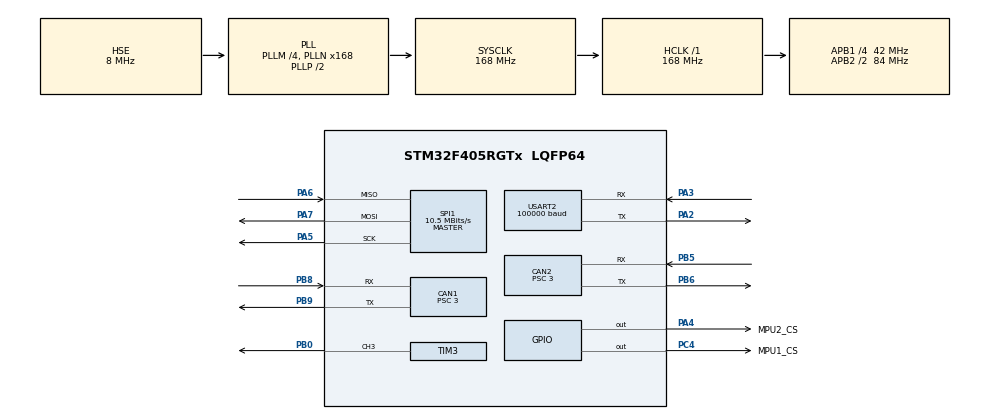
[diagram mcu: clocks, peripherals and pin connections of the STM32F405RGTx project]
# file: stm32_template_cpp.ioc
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CAN1.ABOM=ENABLE
CAN1.BS1=CAN_BS1_9TQ
CAN1.BS2=CAN_BS2_4TQ
CAN1.CalculateBaudRate=1000000
CAN1.CalculateTimeBit=1000
CAN1.CalculateTimeQuantum=71.42857142857143
CAN1.NART=ENABLE
CAN1.Prescaler=3
CAN2.ABOM=ENABLE
CAN2.BS1=CAN_BS1_9TQ
CAN2.BS2=CAN_BS2_4TQ
CAN2.CalculateBaudRate=1000000
CAN2.CalculateTimeBit=1000
CAN2.CalculateTimeQuantum=71.42857142857143
CAN2.NART=ENABLE
CAN2.Prescaler=3
Dma.Request0=USART2_RX
Dma.USART2_RX.0.Direction=DMA_PERIPH_TO_MEMORY
Dma.USART2_RX.0.FIFOMode=DMA_FIFOMODE_DISABLE
Dma.USART2_RX.0.Instance=DMA1_Stream5
Dma.USART2_RX.0.MemDataAlignment=DMA_MDATAALIGN_BYTE
Dma.USART2_RX.0.MemInc=DMA_MINC_ENABLE
Dma.USART2_RX.0.Mode=DMA_CIRCULAR
Dma.USART2_RX.0.PeriphDataAlignment=DMA_PDATAALIGN_BYTE
Dma.USART2_RX.0.PeriphInc=DMA_PINC_DISABLE
Dma.USART2_RX.0.Priority=DMA_PRIORITY_HIGH
FREERTOS.INCLUDE_vTaskDelayUntil=1
FREERTOS.Tasks01=defaultTask,0,128,StartDefaultTask,Default,NULL,Dynamic,NULL,NULL
FREERTOS.configMINIMAL_STACK_SIZE=64
Mcu.Family=STM32F4
Mcu.Name=STM32F405RGTx
Mcu.Package=LQFP64
NVIC.CAN1_RX0_IRQn=true\:5\:0\:false\:false\:true\:true\:true\:true\:true
NVIC.CAN1_RX1_IRQn=true\:5\:0\:false\:false\:true\:true\:true\:true\:true
NVIC.CAN2_RX0_IRQn=true\:5\:0\:false\:false\:true\:true\:true\:true\:true
NVIC.CAN2_RX1_IRQn=true\:5\:0\:false\:false\:true\:true\:true\:true\:true
NVIC.DMA1_Stream5_IRQn=true\:5\:0\:false\:false\:true\:true\:false\:true\:true
NVIC.PriorityGroup=NVIC_PRIORITYGROUP_4
NVIC.TIM6_DAC_IRQn=true\:15\:0\:false\:false\:true\:false\:false\:true\:true
NVIC.TIM7_IRQn=true\:5\:0\:false\:false\:true\:true\:true\:true\:true
NVIC.TimeBase=TIM6_DAC_IRQn
NVIC.TimeBaseIP=TIM6
NVIC.USART2_IRQn=true\:5\:0\:false\:false\:true\:true\:true\:true\:true
PA13.Mode=Serial_Wire
PA13.Signal=SYS_JTMS-SWDIO
PA14.Mode=Serial_Wire
PA14.Signal=SYS_JTCK-SWCLK
PA2.Mode=Asynchronous
PA2.Signal=USART2_TX
PA3.Mode=Asynchronous
PA3.Signal=USART2_RX
PA4.GPIO_Label=MPU2_CS
PA4.GPIO_Speed=GPIO_SPEED_FREQ_HIGH
PA4.PinState=GPIO_PIN_SET
PA4.Signal=GPIO_Output
PA5.Mode=Full_Duplex_Master
PA5.Signal=SPI1_SCK
PA6.Mode=Full_Duplex_Master
PA6.Signal=SPI1_MISO
PA7.Mode=Full_Duplex_Master
PA7.Signal=SPI1_MOSI
PB0.Signal=S_TIM3_CH3
PB5.Mode=CAN_Activate
PB5.Signal=CAN2_RX
PB6.Mode=CAN_Activate
PB6.Signal=CAN2_TX
PB8.Mode=CAN_Activate
PB8.Signal=CAN1_RX
PB9.Mode=CAN_Activate
PB9.Signal=CAN1_TX
PC4.GPIO_Label=MPU1_CS
PC4.GPIO_Speed=GPIO_SPEED_FREQ_HIGH
PC4.PinState=GPIO_PIN_SET
PC4.Signal=GPIO_Output
PH0-OSC_IN.Mode=HSE-External-Oscillator
PH0-OSC_IN.Signal=RCC_OSC_IN
PH1-OSC_OUT.Mode=HSE-External-Oscillator
PH1-OSC_OUT.Signal=RCC_OSC_OUT
ProjectManager.HeapSize=0x200
ProjectManager.StackSize=0x400
ProjectManager.TargetToolchain=MDK-ARM V5.32
RCC.48MHZClocksFreq_Value=84000000
RCC.AHBFreq_Value=168000000
RCC.APB1CLKDivider=RCC_HCLK_DIV4
RCC.APB1Freq_Value=42000000
RCC.APB1TimFreq_Value=84000000
RCC.APB2CLKDivider=RCC_HCLK_DIV2
RCC.APB2Freq_Value=84000000
RCC.APB2TimFreq_Value=168000000
RCC.CortexFreq_Value=168000000
RCC.HCLKFreq_Value=168000000
RCC.HSE_VALUE=8000000
RCC.HSI_VALUE=16000000
RCC.LSE_VALUE=32768
RCC.PLLM=4
RCC.PLLN=168
RCC.PLLSourceVirtual=RCC_PLLSOURCE_HSE
RCC.SYSCLKFreq_VALUE=168000000
RCC.SYSCLKSource=RCC_SYSCLKSOURCE_PLLCLK
RCC.VCOOutputFreq_Value=336000000
SH.S_TIM3_CH3.0=TIM3_CH3,PWM Generation3 CH3
SPI1.BaudRatePrescaler=SPI_BAUDRATEPRESCALER_8
SPI1.CalculateBaudRate=10.5 MBits/s
SPI1.Direction=SPI_DIRECTION_2LINES
SPI1.Mode=SPI_MODE_MASTER
SPI1.VirtualType=VM_MASTER
TIM3.Channel-PWM\ Generation3\ CH3=TIM_CHANNEL_3
TIM3.Period=999
TIM3.Prescaler=83
TIM7.Prescaler=83
USART2.BaudRate=100000
USART2.Mode=MODE_RX
USART2.Parity=PARITY_EVEN
USART2.VirtualMode=VM_ASYNC
VP_FREERTOS_VS_CMSIS_V1.Mode=CMSIS_V1
VP_SYS_VS_tim6.Mode=TIM6
VP_TIM3_VS_ClockSourceINT.Mode=Internal
VP_TIM7_VS_ClockSourceINT.Mode=Enable_Timer
board=custom

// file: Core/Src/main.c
/* USER CODE BEGIN Header */
/**
  ******************************************************************************
  * @file           : main.c
  * @brief          : Main program body
  ******************************************************************************
  * @attention
  *
  * Copyright (c) 2023 STMicroelectronics.
  * All rights reserved.
  *
  * This software is licensed under terms that can be found in the LICENSE file
  * in the root directory of this software component.
  * If no LICENSE file comes with this software, it is provided AS-IS.
  *
  ******************************************************************************
  */
/* USER CODE END Header */
#include "main.h"
#include "cmsis_os.h"

/* USER CODE BEGIN Includes */
#include "system_start.h"
/* USER CODE END Includes */

CAN_HandleTypeDef hcan1;
CAN_HandleTypeDef hcan2;

osThreadId defaultTaskHandle;

void SystemClock_Config(void);
static void MX_GPIO_Init(void);
static void MX_DMA_Init(void);
static void MX_CAN1_Init(void);
static void MX_CAN2_Init(void);
static void MX_USART2_UART_Init(void);
static void MX_TIM7_Init(void);
static void MX_SPI1_Init(void);
static void MX_TIM3_Init(void);
void StartDefaultTask(void const * argument);

int main(void)
{
  /* USER CODE BEGIN 1 */
	//__disable_irq();
  /* USER CODE END 1 */

  /* MCU Configuration--------------------------------------------------------*/

  /* Reset of all peripherals, Initializes the Flash interface and the Systick. */
  HAL_Init();

  /* Configure the system clock */
  SystemClock_Config();

  /* Initialize all configured peripherals */
  MX_GPIO_Init();
  MX_DMA_Init();
  MX_CAN1_Init();
  MX_CAN2_Init();
  MX_USART2_UART_Init();
  MX_TIM7_Init();
  MX_SPI1_Init();
  MX_TIM3_Init();
  /* USER CODE BEGIN 2 */
	System_Init();
	//__enable_irq();
  /* USER CODE END 2 */

  /* Create the thread(s) */
  /* definition and creation of defaultTask */
  osThreadDef(defaultTask, StartDefaultTask, osPriorityNormal, 0, 128);
  defaultTaskHandle = osThreadCreate(osThread(defaultTask), NULL);

  /* Start scheduler */
  osKernelStart();

  /* We should never get here as control is now taken by the scheduler */
  /* Infinite loop */
  while (1)
  {

  }
}

void SystemClock_Config(void)
{
  RCC_OscInitTypeDef RCC_OscInitStruct = {0};
  RCC_ClkInitTypeDef RCC_ClkInitStruct = {0};

  /** Configure the main internal regulator output voltage
  */
  __HAL_RCC_PWR_CLK_ENABLE();
  __HAL_PWR_VOLTAGESCALING_CONFIG(PWR_REGULATOR_VOLTAGE_SCALE1);

  /** Initializes the RCC Oscillators according to the specified parameters
  * in the RCC_OscInitTypeDef structure.
  */
  RCC_OscInitStruct.OscillatorType = RCC_OSCILLATORTYPE_HSE;
  RCC_OscInitStruct.HSEState = RCC_HSE_ON;
  RCC_OscInitStruct.PLL.PLLState = RCC_PLL_ON;
  RCC_OscInitStruct.PLL.PLLSource = RCC_PLLSOURCE_HSE;
  RCC_OscInitStruct.PLL.PLLM = 4;
  RCC_OscInitStruct.PLL.PLLN = 168;
  RCC_OscInitStruct.PLL.PLLP = RCC_PLLP_DIV2;
  RCC_OscInitStruct.PLL.PLLQ = 4;
  if (HAL_RCC_OscConfig(&RCC_OscInitStruct) != HAL_OK)
  {
    Error_Handler();
  }

  /** Initializes the CPU, AHB and APB buses clocks
  */
  RCC_ClkInitStruct.ClockType = RCC_CLOCKTYPE_HCLK|RCC_CLOCKTYPE_SYSCLK
                              |RCC_CLOCKTYPE_PCLK1|RCC_CLOCKTYPE_PCLK2;
  RCC_ClkInitStruct.SYSCLKSource = RCC_SYSCLKSOURCE_PLLCLK;
  RCC_ClkInitStruct.AHBCLKDivider = RCC_SYSCLK_DIV1;
  RCC_ClkInitStruct.APB1CLKDivider = RCC_HCLK_DIV4;
  RCC_ClkInitStruct.APB2CLKDivider = RCC_HCLK_DIV2;

  if (HAL_RCC_ClockConfig(&RCC_ClkInitStruct, FLASH_LATENCY_5) != HAL_OK)
  {
    Error_Handler();
  }
}

static void MX_CAN1_Init(void)
{

  hcan1.Instance = CAN1;
  hcan1.Init.Prescaler = 3;
  hcan1.Init.Mode = CAN_MODE_NORMAL;
  hcan1.Init.SyncJumpWidth = CAN_SJW_1TQ;
  hcan1.Init.TimeSeg1 = CAN_BS1_9TQ;
  hcan1.Init.TimeSeg2 = CAN_BS2_4TQ;
  hcan1.Init.TimeTriggeredMode = DISABLE;
  hcan1.Init.AutoBusOff = ENABLE;
  hcan1.Init.AutoWakeUp = DISABLE;
  hcan1.Init.AutoRetransmission = ENABLE;
  hcan1.Init.ReceiveFifoLocked = DISABLE;
  hcan1.Init.TransmitFifoPriority = DISABLE;
  if (HAL_CAN_Init(&hcan1) != HAL_OK)
  {
    Error_Handler();
  }

}

static void MX_CAN2_Init(void)
{

  hcan2.Instance = CAN2;
  hcan2.Init.Prescaler = 3;
  hcan2.Init.Mode = CAN_MODE_NORMAL;
  hcan2.Init.SyncJumpWidth = CAN_SJW_1TQ;
  hcan2.Init.TimeSeg1 = CAN_BS1_9TQ;
  hcan2.Init.TimeSeg2 = CAN_BS2_4TQ;
  hcan2.Init.TimeTriggeredMode = DISABLE;
  hcan2.Init.AutoBusOff = ENABLE;
  hcan2.Init.AutoWakeUp = DISABLE;
  hcan2.Init.AutoRetransmission = ENABLE;
  hcan2.Init.ReceiveFifoLocked = DISABLE;
  hcan2.Init.TransmitFifoPriority = DISABLE;
  if (HAL_CAN_Init(&hcan2) != HAL_OK)
  {
    Error_Handler();
  }

}

static void MX_SPI1_Init(void)
{

  LL_SPI_InitTypeDef SPI_InitStruct = {0};

  LL_GPIO_InitTypeDef GPIO_InitStruct = {0};

  /* Peripheral clock enable */
  LL_APB2_GRP1_EnableClock(LL_APB2_GRP1_PERIPH_SPI1);

  LL_AHB1_GRP1_EnableClock(LL_AHB1_GRP1_PERIPH_GPIOA);
  /**SPI1 GPIO Configuration
  PA5   ------> SPI1_SCK
  PA6   ------> SPI1_MISO
  PA7   ------> SPI1_MOSI
  */
  GPIO_InitStruct.Pin = LL_GPIO_PIN_5|LL_GPIO_PIN_6|LL_GPIO_PIN_7;
  GPIO_InitStruct.Mode = LL_GPIO_MODE_ALTERNATE;
  GPIO_InitStruct.Speed = LL_GPIO_SPEED_FREQ_VERY_HIGH;
  GPIO_InitStruct.OutputType = LL_GPIO_OUTPUT_PUSHPULL;
  GPIO_InitStruct.Pull = LL_GPIO_PULL_NO;
  GPIO_InitStruct.Alternate = LL_GPIO_AF_5;
  LL_GPIO_Init(GPIOA, &GPIO_InitStruct);

  /* SPI1 parameter configuration*/
  SPI_InitStruct.TransferDirection = LL_SPI_FULL_DUPLEX;
  SPI_InitStruct.Mode = LL_SPI_MODE_MASTER;
  SPI_InitStruct.DataWidth = LL_SPI_DATAWIDTH_8BIT;
  SPI_InitStruct.ClockPolarity = LL_SPI_POLARITY_LOW;
  SPI_InitStruct.ClockPhase = LL_SPI_PHASE_1EDGE;
  SPI_InitStruct.NSS = LL_SPI_NSS_SOFT;
  SPI_InitStruct.BaudRate = LL_SPI_BAUDRATEPRESCALER_DIV8;
  SPI_InitStruct.BitOrder = LL_SPI_MSB_FIRST;
  SPI_InitStruct.CRCCalculation = LL_SPI_CRCCALCULATION_DISABLE;
  SPI_InitStruct.CRCPoly = 10;
  LL_SPI_Init(SPI1, &SPI_InitStruct);
  LL_SPI_SetStandard(SPI1, LL_SPI_PROTOCOL_MOTOROLA);

}

static void MX_TIM3_Init(void)
{

  LL_TIM_InitTypeDef TIM_InitStruct = {0};
  LL_TIM_OC_InitTypeDef TIM_OC_InitStruct = {0};

  LL_GPIO_InitTypeDef GPIO_InitStruct = {0};

  /* Peripheral clock enable */
  LL_APB1_GRP1_EnableClock(LL_APB1_GRP1_PERIPH_TIM3);

  TIM_InitStruct.Prescaler = 83;
  TIM_InitStruct.CounterMode = LL_TIM_COUNTERMODE_UP;
  TIM_InitStruct.Autoreload = 999;
  TIM_InitStruct.ClockDivision = LL_TIM_CLOCKDIVISION_DIV1;
  LL_TIM_Init(TIM3, &TIM_InitStruct);
  LL_TIM_DisableARRPreload(TIM3);
  LL_TIM_SetClockSource(TIM3, LL_TIM_CLOCKSOURCE_INTERNAL);
  LL_TIM_OC_EnablePreload(TIM3, LL_TIM_CHANNEL_CH3);
  TIM_OC_InitStruct.OCMode = LL_TIM_OCMODE_PWM1;
  TIM_OC_InitStruct.OCState = LL_TIM_OCSTATE_DISABLE;
  TIM_OC_InitStruct.OCNState = LL_TIM_OCSTATE_DISABLE;
  TIM_OC_InitStruct.CompareValue = 0;
  TIM_OC_InitStruct.OCPolarity = LL_TIM_OCPOLARITY_HIGH;
  LL_TIM_OC_Init(TIM3, LL_TIM_CHANNEL_CH3, &TIM_OC_InitStruct);
  LL_TIM_OC_DisableFast(TIM3, LL_TIM_CHANNEL_CH3);
  LL_TIM_SetTriggerOutput(TIM3, LL_TIM_TRGO_RESET);
  LL_TIM_DisableMasterSlaveMode(TIM3);
  LL_AHB1_GRP1_EnableClock(LL_AHB1_GRP1_PERIPH_GPIOB);
  /**TIM3 GPIO Configuration
  PB0   ------> TIM3_CH3
  */
  GPIO_InitStruct.Pin = LL_GPIO_PIN_0;
  GPIO_InitStruct.Mode = LL_GPIO_MODE_ALTERNATE;
  GPIO_InitStruct.Speed = LL_GPIO_SPEED_FREQ_LOW;
  GPIO_InitStruct.OutputType = LL_GPIO_OUTPUT_PUSHPULL;
  GPIO_InitStruct.Pull = LL_GPIO_PULL_NO;
  GPIO_InitStruct.Alternate = LL_GPIO_AF_2;
  LL_GPIO_Init(GPIOB, &GPIO_InitStruct);

}

static void MX_TIM7_Init(void)
{

  LL_TIM_InitTypeDef TIM_InitStruct = {0};

  /* Peripheral clock enable */
  LL_APB1_GRP1_EnableClock(LL_APB1_GRP1_PERIPH_TIM7);

  /* TIM7 interrupt Init */
  NVIC_SetPriority(TIM7_IRQn, NVIC_EncodePriority(NVIC_GetPriorityGrouping(),5, 0));
  NVIC_EnableIRQ(TIM7_IRQn);

  TIM_InitStruct.Prescaler = 83;
  TIM_InitStruct.CounterMode = LL_TIM_COUNTERMODE_UP;
  TIM_InitStruct.Autoreload = 65535;
  LL_TIM_Init(TIM7, &TIM_InitStruct);
  LL_TIM_DisableARRPreload(TIM7);
  LL_TIM_SetTriggerOutput(TIM7, LL_TIM_TRGO_RESET);
  LL_TIM_DisableMasterSlaveMode(TIM7);

}

static void MX_USART2_UART_Init(void)
{

  LL_USART_InitTypeDef USART_InitStruct = {0};

  LL_GPIO_InitTypeDef GPIO_InitStruct = {0};

  /* Peripheral clock enable */
  LL_APB1_GRP1_EnableClock(LL_APB1_GRP1_PERIPH_USART2);

  LL_AHB1_GRP1_EnableClock(LL_AHB1_GRP1_PERIPH_GPIOA);
  /**USART2 GPIO Configuration
  PA2   ------> USART2_TX
  PA3   ------> USART2_RX
  */
  GPIO_InitStruct.Pin = LL_GPIO_PIN_2|LL_GPIO_PIN_3;
  GPIO_InitStruct.Mode = LL_GPIO_MODE_ALTERNATE;
  GPIO_InitStruct.Speed = LL_GPIO_SPEED_FREQ_VERY_HIGH;
  GPIO_InitStruct.OutputType = LL_GPIO_OUTPUT_PUSHPULL;
  GPIO_InitStruct.Pull = LL_GPIO_PULL_NO;
  GPIO_InitStruct.Alternate = LL_GPIO_AF_7;
  LL_GPIO_Init(GPIOA, &GPIO_InitStruct);

  /* USART2 DMA Init */

  /* USART2_RX Init */
  LL_DMA_SetChannelSelection(DMA1, LL_DMA_STREAM_5, LL_DMA_CHANNEL_4);

  LL_DMA_SetDataTransferDirection(DMA1, LL_DMA_STREAM_5, LL_DMA_DIRECTION_PERIPH_TO_MEMORY);

  LL_DMA_SetStreamPriorityLevel(DMA1, LL_DMA_STREAM_5, LL_DMA_PRIORITY_HIGH);

  LL_DMA_SetMode(DMA1, LL_DMA_STREAM_5, LL_DMA_MODE_CIRCULAR);

  LL_DMA_SetPeriphIncMode(DMA1, LL_DMA_STREAM_5, LL_DMA_PERIPH_NOINCREMENT);

  LL_DMA_SetMemoryIncMode(DMA1, LL_DMA_STREAM_5, LL_DMA_MEMORY_INCREMENT);

  LL_DMA_SetPeriphSize(DMA1, LL_DMA_STREAM_5, LL_DMA_PDATAALIGN_BYTE);

  LL_DMA_SetMemorySize(DMA1, LL_DMA_STREAM_5, LL_DMA_MDATAALIGN_BYTE);

  LL_DMA_DisableFifoMode(DMA1, LL_DMA_STREAM_5);

  /* USART2 interrupt Init */
  NVIC_SetPriority(USART2_IRQn, NVIC_EncodePriority(NVIC_GetPriorityGrouping(),5, 0));
  NVIC_EnableIRQ(USART2_IRQn);

  USART_InitStruct.BaudRate = 100000;
  USART_InitStruct.DataWidth = LL_USART_DATAWIDTH_8B;
  USART_InitStruct.StopBits = LL_USART_STOPBITS_1;
  USART_InitStruct.Parity = LL_USART_PARITY_EVEN;
  USART_InitStruct.TransferDirection = LL_USART_DIRECTION_RX;
  USART_InitStruct.HardwareFlowControl = LL_USART_HWCONTROL_NONE;
  USART_InitStruct.OverSampling = LL_USART_OVERSAMPLING_16;
  LL_USART_Init(USART2, &USART_InitStruct);
  LL_USART_ConfigAsyncMode(USART2);
  LL_USART_Enable(USART2);

}

static void MX_DMA_Init(void)
{

  /* Init with LL driver */
  /* DMA controller clock enable */
  LL_AHB1_GRP1_EnableClock(LL_AHB1_GRP1_PERIPH_DMA1);

  /* DMA interrupt init */
  /* DMA1_Stream5_IRQn interrupt configuration */
  NVIC_SetPriority(DMA1_Stream5_IRQn, NVIC_EncodePriority(NVIC_GetPriorityGrouping(),5, 0));
  NVIC_EnableIRQ(DMA1_Stream5_IRQn);

}

static void MX_GPIO_Init(void)
{
  GPIO_InitTypeDef GPIO_InitStruct = {0};

  /* GPIO Ports Clock Enable */
  __HAL_RCC_GPIOH_CLK_ENABLE();
  __HAL_RCC_GPIOA_CLK_ENABLE();
  __HAL_RCC_GPIOC_CLK_ENABLE();
  __HAL_RCC_GPIOB_CLK_ENABLE();

  /*Configure GPIO pin Output Level */
  HAL_GPIO_WritePin(MPU2_CS_GPIO_Port, MPU2_CS_Pin, GPIO_PIN_SET);

  /*Configure GPIO pin Output Level */
  HAL_GPIO_WritePin(MPU1_CS_GPIO_Port, MPU1_CS_Pin, GPIO_PIN_SET);

  /*Configure GPIO pin : MPU2_CS_Pin */
  GPIO_InitStruct.Pin = MPU2_CS_Pin;
  GPIO_InitStruct.Mode = GPIO_MODE_OUTPUT_PP;
  GPIO_InitStruct.Pull = GPIO_NOPULL;
  GPIO_InitStruct.Speed = GPIO_SPEED_FREQ_HIGH;
  HAL_GPIO_Init(MPU2_CS_GPIO_Port, &GPIO_InitStruct);

  /*Configure GPIO pin : MPU1_CS_Pin */
  GPIO_InitStruct.Pin = MPU1_CS_Pin;
  GPIO_InitStruct.Mode = GPIO_MODE_OUTPUT_PP;
  GPIO_InitStruct.Pull = GPIO_NOPULL;
  GPIO_InitStruct.Speed = GPIO_SPEED_FREQ_HIGH;
  HAL_GPIO_Init(MPU1_CS_GPIO_Port, &GPIO_InitStruct);

}

void StartDefaultTask(void const * argument)
{
  /* USER CODE BEGIN 5 */
  /* Infinite loop */
  for(;;)
  {
		RTOS_Init();
		osThreadTerminate (defaultTaskHandle);
  }
  /* USER CODE END 5 */
}

void HAL_TIM_PeriodElapsedCallback(TIM_HandleTypeDef *htim)
{
  if (htim->Instance == TIM6) {
    HAL_IncTick();
  }
}

void Error_Handler(void)
{
  __disable_irq();
  while (1)
  {
  }
}
